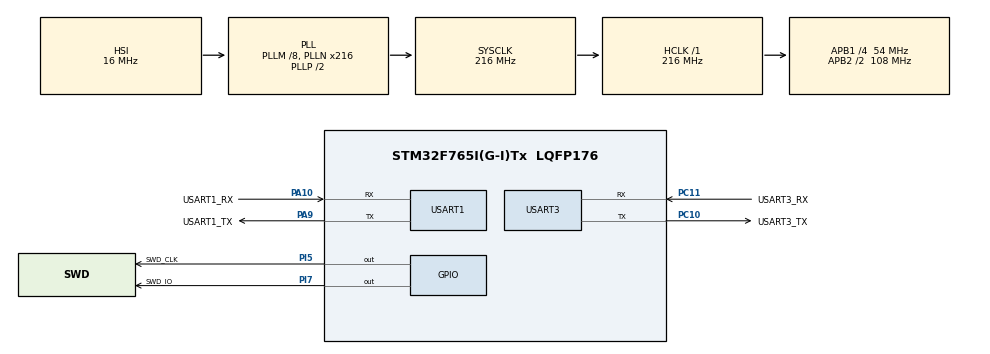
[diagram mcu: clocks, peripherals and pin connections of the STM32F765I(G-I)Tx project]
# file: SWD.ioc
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Mcu.Family=STM32F7
Mcu.Name=STM32F765I(G-I)Tx
Mcu.Package=LQFP176
NVIC.PriorityGroup=NVIC_PRIORITYGROUP_4
NVIC.USART1_IRQn=true\:0\:0\:false\:false\:true\:true
NVIC.USART3_IRQn=true\:0\:0\:false\:false\:true\:true
PA10.GPIO_Label=USART1_RX
PA10.Mode=Asynchronous
PA10.Signal=USART1_RX
PA13.Mode=Serial_Wire
PA13.Signal=SYS_JTMS-SWDIO
PA14.Mode=Serial_Wire
PA14.Signal=SYS_JTCK-SWCLK
PA9.GPIO_Label=USART1_TX
PA9.Mode=Asynchronous
PA9.Signal=USART1_TX
PC10.GPIO_Label=USART3_TX
PC10.Mode=Asynchronous
PC10.Signal=USART3_TX
PC11.GPIO_Label=USART3_RX
PC11.Mode=Asynchronous
PC11.Signal=USART3_RX
PH0/OSC_IN.Mode=HSE-External-Oscillator
PH0/OSC_IN.Signal=RCC_OSC_IN
PH1/OSC_OUT.Mode=HSE-External-Oscillator
PH1/OSC_OUT.Signal=RCC_OSC_OUT
PI5.GPIO_Label=SWD_CLK
PI5.GPIO_ModeDefaultOutputPP=GPIO_MODE_OUTPUT_OD
PI5.GPIO_PuPd=GPIO_PULLUP
PI5.GPIO_Speed=GPIO_SPEED_FREQ_VERY_HIGH
PI5.PinState=GPIO_PIN_RESET
PI5.Signal=GPIO_Output
PI7.GPIO_Label=SWD_IO
PI7.GPIO_ModeDefaultOutputPP=GPIO_MODE_OUTPUT_OD
PI7.GPIO_PuPd=GPIO_PULLUP
PI7.GPIO_Speed=GPIO_SPEED_FREQ_VERY_HIGH
PI7.Signal=GPIO_Output
ProjectManager.HeapSize=0x200
ProjectManager.StackSize=0x400
ProjectManager.TargetToolchain=MDK-ARM V5
RCC.AHBFreq_Value=216000000
RCC.APB1CLKDivider=RCC_HCLK_DIV4
RCC.APB1Freq_Value=54000000
RCC.APB1TimFreq_Value=108000000
RCC.APB2CLKDivider=RCC_HCLK_DIV2
RCC.APB2Freq_Value=108000000
RCC.APB2TimFreq_Value=216000000
RCC.CortexFreq_Value=216000000
RCC.HCLKFreq_Value=216000000
RCC.HSE_VALUE=25000000
RCC.HSI_VALUE=16000000
RCC.LSE_VALUE=32768
RCC.PLLM=8
RCC.PLLN=216
RCC.SYSCLKFreq_VALUE=216000000
RCC.SYSCLKSource=RCC_SYSCLKSOURCE_PLLCLK
RCC.USBFreq_Value=216000000
RCC.VCOOutputFreq_Value=432000000
USART1.VirtualMode-Asynchronous=VM_ASYNC
USART1.WordLength=WORDLENGTH_8B
USART3.VirtualMode-Asynchronous=VM_ASYNC
USART3.WordLength=WORDLENGTH_8B
board=SWD

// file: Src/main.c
/**
  ******************************************************************************
  * @file           : main.c
  * @brief          : Main program body
  ******************************************************************************
  ** This notice applies to any and all portions of this file
  * that are not between comment pairs USER CODE BEGIN and
  * USER CODE END. Other portions of this file, whether
  * inserted by the user or by software development tools
  * are owned by their respective copyright owners.
  *
  * COPYRIGHT(c) 2019 STMicroelectronics
  *
  * Redistribution and use in source and binary forms, with or without modification,
  * are permitted provided that the following conditions are met:
  *   1. Redistributions of source code must retain the above copyright notice,
  *      this list of conditions and the following disclaimer.
  *   2. Redistributions in binary form must reproduce the above copyright notice,
  *      this list of conditions and the following disclaimer in the documentation
  *      and/or other materials provided with the distribution.
  *   3. Neither the name of STMicroelectronics nor the names of its contributors
  *      may be used to endorse or promote products derived from this software
  *      without specific prior written permission.
  *
  * THIS SOFTWARE IS PROVIDED BY THE COPYRIGHT HOLDERS AND CONTRIBUTORS "AS IS"
  * AND ANY EXPRESS OR IMPLIED WARRANTIES, INCLUDING, BUT NOT LIMITED TO, THE
  * IMPLIED WARRANTIES OF MERCHANTABILITY AND FITNESS FOR A PARTICULAR PURPOSE ARE
  * DISCLAIMED. IN NO EVENT SHALL THE COPYRIGHT HOLDER OR CONTRIBUTORS BE LIABLE
  * FOR ANY DIRECT, INDIRECT, INCIDENTAL, SPECIAL, EXEMPLARY, OR CONSEQUENTIAL
  * DAMAGES (INCLUDING, BUT NOT LIMITED TO, PROCUREMENT OF SUBSTITUTE GOODS OR
  * SERVICES; LOSS OF USE, DATA, OR PROFITS; OR BUSINESS INTERRUPTION) HOWEVER
  * CAUSED AND ON ANY THEORY OF LIABILITY, WHETHER IN CONTRACT, STRICT LIABILITY,
  * OR TORT (INCLUDING NEGLIGENCE OR OTHERWISE) ARISING IN ANY WAY OUT OF THE USE
  * OF THIS SOFTWARE, EVEN IF ADVISED OF THE POSSIBILITY OF SUCH DAMAGE.
  *
  ******************************************************************************
  */

/* USER CODE BEGIN Includes */
#include "headers.h"
/* USER CODE END Includes */

/* USER CODE BEGIN PV */
/* Private variables ---------------------------------------------------------*/

/* USER CODE END PV */

void SystemClock_Config(void);
void startUpPrompts(void);
/* USER CODE BEGIN PFP */
/* Private function prototypes -----------------------------------------------*/

/* USER CODE END PFP */
uint16_t cmdWriteLoc=0,cmdDispLoc=0,cmdWriteLoc2=0,cmdWriteLoc3=0;uint8_t cmdrcvdflag=0;

int main(void)
{
  /* USER CODE BEGIN 1 */
	uint8_t ch=0;
	GEN_CMD gencmd;
  /* USER CODE END 1 */

  /* MCU Configuration----------------------------------------------------------*/

  /* Reset of all peripherals, Initializes the Flash interface and the Systick. */
  HAL_Init();

  /* Configure the system clock */
  SystemClock_Config();

  /* Initialize all configured peripherals */
  MX_GPIO_Init();
  MX_USART1_UART_Init();
  MX_USART3_UART_Init();
  /* USER CODE BEGIN 2 */
	startUpPrompts();
	HAL_UART_Receive_IT(&huart1, &ch,2);
	HAL_UART_Receive_IT(&huart3, &ch,2);
  /* USER CODE END 2 */

  /* Infinite loop */
  while (1)
  {
			cmdrcvdflag=0;
			clrbuff(cmdresbuff.cmd);
			DutPrompt();
			flushBuff();
			while(cmdrcvdflag==0){
					if(cmdDispLoc<cmdWriteLoc){
							HAL_UART_Transmit(&huart1,&cmdresbuff.cmd[cmdDispLoc],1,100);
							HAL_UART_Transmit(&huart3,&cmdresbuff.cmd[cmdDispLoc],1,100);
							cmdDispLoc++;
					}
			}
			cmdDispLoc=0;
			shell(cmdresbuff.cmd,&gencmd);
			clrbuff(cmdresbuff.cmd);
			flushBuff();
  /* USER CODE END WHILE */

  }

}

void startUpPrompts(){
		uint8_t prompt[]="\r\n/********* SWD DEMO CONSOLE ***********/\r\n\tMC FW Version : 1.0.0\r\n\tMC Author     : Rohit Bhardwaj";
		HAL_UART_Transmit(&huart1,(uint8_t *)prompt,strlen((char *)prompt),100);
		HAL_UART_Transmit(&huart3,(uint8_t *)prompt,strlen((char *)prompt),100);
}
void SystemClock_Config(void)
{

  RCC_OscInitTypeDef RCC_OscInitStruct;
  RCC_ClkInitTypeDef RCC_ClkInitStruct;
  RCC_PeriphCLKInitTypeDef PeriphClkInitStruct;

    /**Configure the main internal regulator output voltage
    */
  __HAL_RCC_PWR_CLK_ENABLE();

  __HAL_PWR_VOLTAGESCALING_CONFIG(PWR_REGULATOR_VOLTAGE_SCALE1);

    /**Initializes the CPU, AHB and APB busses clocks
    */
  RCC_OscInitStruct.OscillatorType = RCC_OSCILLATORTYPE_HSI;
  RCC_OscInitStruct.HSIState = RCC_HSI_ON;
  RCC_OscInitStruct.HSICalibrationValue = 16;
  RCC_OscInitStruct.PLL.PLLState = RCC_PLL_ON;
  RCC_OscInitStruct.PLL.PLLSource = RCC_PLLSOURCE_HSI;
  RCC_OscInitStruct.PLL.PLLM = 8;
  RCC_OscInitStruct.PLL.PLLN = 216;
  RCC_OscInitStruct.PLL.PLLP = RCC_PLLP_DIV2;
  RCC_OscInitStruct.PLL.PLLQ = 2;
  if (HAL_RCC_OscConfig(&RCC_OscInitStruct) != HAL_OK)
  {
    _Error_Handler(__FILE__, __LINE__);
  }

    /**Activate the Over-Drive mode
    */
  if (HAL_PWREx_EnableOverDrive() != HAL_OK)
  {
    _Error_Handler(__FILE__, __LINE__);
  }

    /**Initializes the CPU, AHB and APB busses clocks
    */
  RCC_ClkInitStruct.ClockType = RCC_CLOCKTYPE_HCLK|RCC_CLOCKTYPE_SYSCLK
                              |RCC_CLOCKTYPE_PCLK1|RCC_CLOCKTYPE_PCLK2;
  RCC_ClkInitStruct.SYSCLKSource = RCC_SYSCLKSOURCE_PLLCLK;
  RCC_ClkInitStruct.AHBCLKDivider = RCC_SYSCLK_DIV1;
  RCC_ClkInitStruct.APB1CLKDivider = RCC_HCLK_DIV4;
  RCC_ClkInitStruct.APB2CLKDivider = RCC_HCLK_DIV2;

  if (HAL_RCC_ClockConfig(&RCC_ClkInitStruct, FLASH_LATENCY_7) != HAL_OK)
  {
    _Error_Handler(__FILE__, __LINE__);
  }

  PeriphClkInitStruct.PeriphClockSelection = RCC_PERIPHCLK_USART1|RCC_PERIPHCLK_USART3;
  PeriphClkInitStruct.Usart1ClockSelection = RCC_USART1CLKSOURCE_PCLK2;
  PeriphClkInitStruct.Usart3ClockSelection = RCC_USART3CLKSOURCE_PCLK1;
  if (HAL_RCCEx_PeriphCLKConfig(&PeriphClkInitStruct) != HAL_OK)
  {
    _Error_Handler(__FILE__, __LINE__);
  }

    /**Configure the Systick interrupt time
    */
  HAL_SYSTICK_Config(HAL_RCC_GetHCLKFreq()/1000);

    /**Configure the Systick
    */
  HAL_SYSTICK_CLKSourceConfig(SYSTICK_CLKSOURCE_HCLK);

  /* SysTick_IRQn interrupt configuration */
  HAL_NVIC_SetPriority(SysTick_IRQn, 0, 0);
}

void _Error_Handler(char *file, int line)
{
  while(1)
  {
  }
}

/************************ (C) COPYRIGHT STMicroelectronics *****END OF FILE****/
